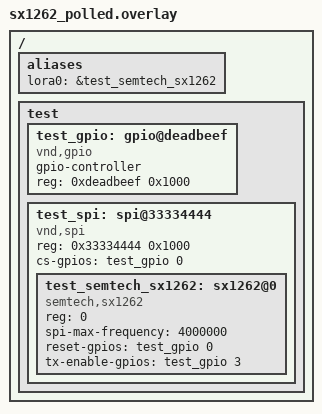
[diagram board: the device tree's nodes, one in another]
/*
 * Copyright The Zephyr Project Contributors
 * SPDX-License-Identifier: Apache-2.0
 */

/* An SX1262 without BUSY and DIO1 lines: the driver waits and polls. */

/ {
	aliases {
		lora0 = &test_semtech_sx1262;
	};

	test {
		#address-cells = <1>;
		#size-cells = <1>;

		test_gpio: gpio@deadbeef {
			compatible = "vnd,gpio";
			gpio-controller;
			reg = <0xdeadbeef 0x1000>;
			#gpio-cells = <0x2>;
			status = "okay";
		};

		test_spi: spi@33334444 {
			#address-cells = <1>;
			#size-cells = <0>;
			compatible = "vnd,spi";
			reg = <0x33334444 0x1000>;
			status = "okay";

			cs-gpios = <&test_gpio 0 0>;

			test_semtech_sx1262: sx1262@0 {
				compatible = "semtech,sx1262";
				status = "okay";
				reg = <0>;
				spi-max-frequency = <4000000>;
				reset-gpios = <&test_gpio 0 0>;
				tx-enable-gpios = <&test_gpio 3 0>;
			};
		};
	};
};
